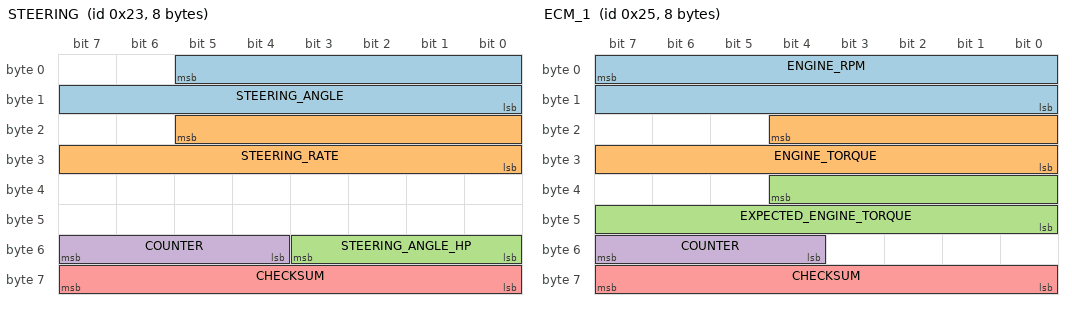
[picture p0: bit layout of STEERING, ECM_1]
BO_ 35 STEERING: 8 XXX
 SG_ STEERING_ANGLE : 5|14@0+ (0.5,-2048) [-2048|2047] "deg" XXX
 SG_ STEERING_RATE : 21|14@0+ (0.5,-2048) [-2048|2047] "deg/s" XXX
 SG_ STEERING_ANGLE_HP : 48|4@1+ (0.1,-0.4) [-0.4|0.4] "deg" XXX
 SG_ COUNTER : 55|4@0+ (1,0) [0|15] "" XXX
 SG_ CHECKSUM : 63|8@0+ (1,0) [0|255] "" XXX

BO_ 37 ECM_1: 8 XXX
 SG_ ENGINE_RPM : 7|16@0+ (1,0) [0|65535] "" XXX
 SG_ ENGINE_TORQUE : 20|13@0+ (0.25,-500) [-500|1547.5] "Nm" XXX
 SG_ EXPECTED_ENGINE_TORQUE : 36|13@0+ (0.25,-500) [-500|1547.5] "Nm" XXX
 SG_ COUNTER : 55|4@0+ (1,0) [0|15] "" XXX
 SG_ CHECKSUM : 63|8@0+ (1,0) [0|255] "" XXX

BO_ 181 ECM_TRQ: 8 XXX
 SG_ ENGINE_TORQ_MAX : 4|13@0+ (.25,-500) [-500|1547.5] "NM" XXX
 SG_ ENGINE_TORQ_MIN : 20|13@0+ (.25,-500) [-500|1547.5] "NM" XXX

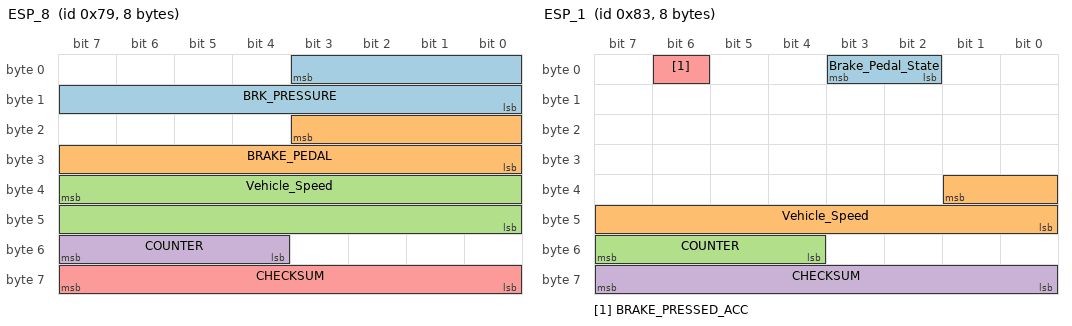
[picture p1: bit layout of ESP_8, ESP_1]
BO_ 121 ESP_8: 8 XXX
 SG_ BRK_PRESSURE : 3|12@0+ (1,0) [0|1] "" XXX
 SG_ BRAKE_PEDAL : 19|12@0+ (1,0) [0|1] "" XXX
 SG_ Vehicle_Speed : 39|16@0+ (0.0078125,0) [0|511.984375] "km/h" XXX
 SG_ COUNTER : 55|4@0+ (1,0) [0|15] "" XXX
 SG_ CHECKSUM : 63|8@0+ (1,0) [0|255] "" XXX

BO_ 131 ESP_1: 8 XXX
 SG_ Brake_Pedal_State : 2|2@1+ (1,0) [0|0] "" XXX
 SG_ Vehicle_Speed : 33|10@0+ (0.5,0) [0|511] "km/h" XXX
 SG_ COUNTER : 55|4@0+ (1,0) [0|15] "" XXX
 SG_ CHECKSUM : 63|8@0+ (1,0) [0|255] "" XXX
 SG_ BRAKE_PRESSED_ACC : 6|1@0+ (1,0) [0|3] "" XXX

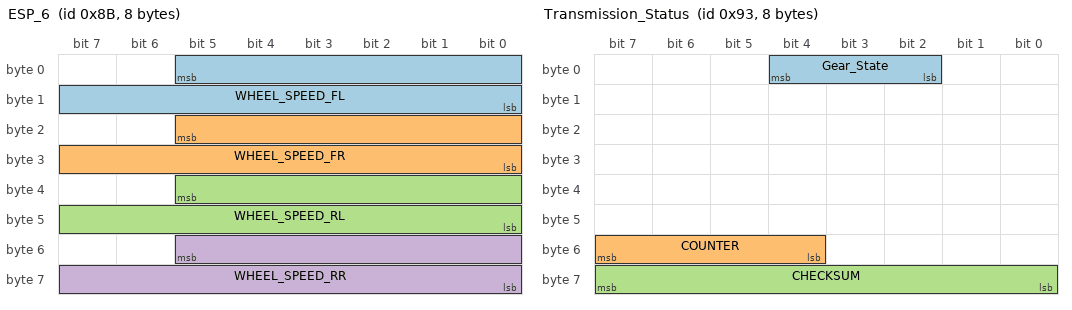
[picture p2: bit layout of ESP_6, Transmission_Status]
BO_ 139 ESP_6: 8 XXX
 SG_ WHEEL_SPEED_FL : 5|14@0+ (0.5,0) [0|8191] "rpm" XXX
 SG_ WHEEL_SPEED_FR : 21|14@0+ (0.5,0) [0|8191] "rpm" XXX
 SG_ WHEEL_SPEED_RL : 37|14@0+ (0.5,0) [0|8191] "rpm" XXX
 SG_ WHEEL_SPEED_RR : 53|14@0+ (0.5,0) [0|8191] "rpm" XXX

BO_ 147 Transmission_Status: 8 XXX
 SG_ Gear_State : 2|3@1+ (1,0) [0|15] "" XXX
 SG_ COUNTER : 55|4@0+ (1,0) [0|15] "" XXX
 SG_ CHECKSUM : 63|8@0+ (1,0) [0|255] "" XXX

BO_ 464 ORC_1: 8 XXX
 SG_ SEATBELT_DRIVER_UNLATCHED : 13|1@0+ (1,0) [0|1] "" XXX

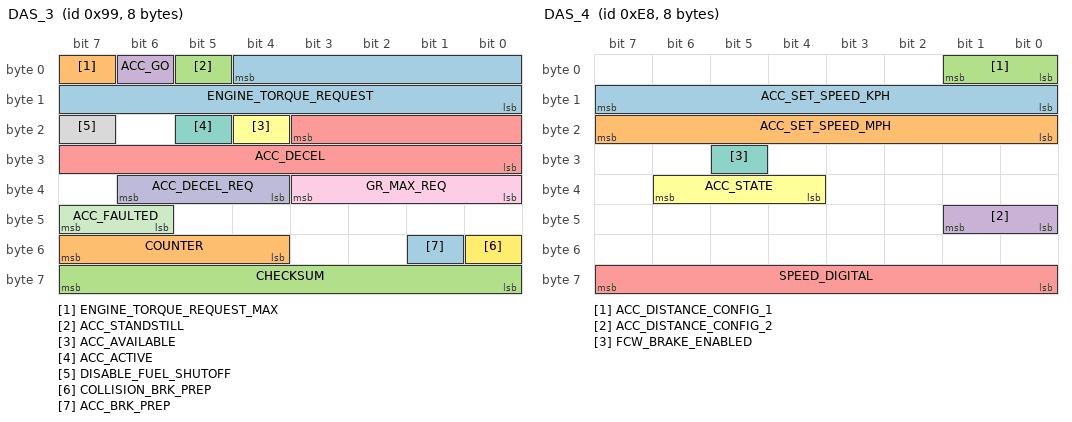
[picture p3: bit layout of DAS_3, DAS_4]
BO_ 153 DAS_3: 8 XXX
 SG_ ENGINE_TORQUE_REQUEST : 4|13@0+ (0.25,-500) [-500|1547.5] "Nm" XXX
 SG_ ENGINE_TORQUE_REQUEST_MAX : 7|1@0+ (1,0) [0|1] "" XXX
 SG_ ACC_STANDSTILL : 5|1@0+ (1,0) [0|1] ""  XXX
 SG_ ACC_GO : 6|1@1+ (1,0) [0|0] "" XXX
 SG_ ACC_DECEL : 19|12@0+ (0.004885,-16) [-16|4] "m/s2" XXX
 SG_ ACC_AVAILABLE : 20|1@0+ (1,0) [0|1] "" XXX
 SG_ ACC_ACTIVE : 21|1@0+ (1,0) [0|1] "" XXX
 SG_ DISABLE_FUEL_SHUTOFF : 23|1@1+ (1,0) [0|0] "" XXX
 SG_ GR_MAX_REQ : 32|4@1+ (1,0) [0|0] "" XXX
 SG_ ACC_DECEL_REQ : 36|3@1+ (1,0) [0|0] "" XXX
 SG_ ACC_FAULTED : 46|2@1+ (1,0) [0|0] "" XXX
 SG_ COLLISION_BRK_PREP : 48|1@1+ (1,0) [0|0] "" XXX
 SG_ ACC_BRK_PREP : 49|1@1+ (1,0) [0|0] "" XXX
 SG_ COUNTER : 55|4@0+ (1,0) [0|15] "" XXX
 SG_ CHECKSUM : 63|8@0+ (1,0) [0|255] "" XXX

BO_ 232 DAS_4: 8 XXX
 SG_ ACC_SET_SPEED_KPH : 15|8@0+ (1,0) [0|3] "km/h" XXX
 SG_ ACC_SET_SPEED_MPH : 23|8@0+ (1,0) [0|3] "mph" XXX
 SG_ ACC_DISTANCE_CONFIG_1 : 1|2@0+ (1,0) [0|3] "" XXX
 SG_ ACC_DISTANCE_CONFIG_2 : 41|2@0+ (1,0) [0|3] "" XXX
 SG_ SPEED_DIGITAL : 63|8@0+ (1,0) [0|255] "mph" XXX
 SG_ ACC_STATE : 38|3@0+ (1,0) [0|7] "" XXX
 SG_ FCW_BRAKE_ENABLED : 29|1@0+ (1,0) [0|1] "" XXX

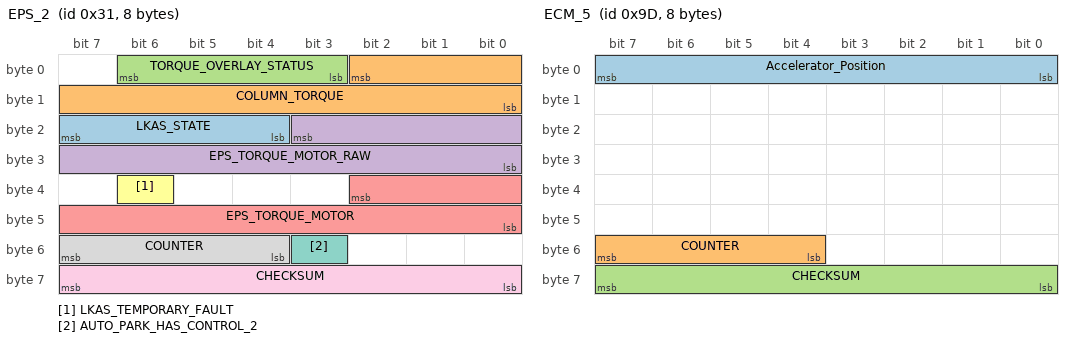
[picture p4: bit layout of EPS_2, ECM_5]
BO_ 49 EPS_2: 8 XXX
 SG_ LKAS_STATE : 23|4@0+ (1,0) [0|15] "" XXX
 SG_ COLUMN_TORQUE : 2|11@0+ (1,-1024) [-1024|1023] "" XXX
 SG_ TORQUE_OVERLAY_STATUS : 6|4@0+ (1,0) [0|15] "" XXX
 SG_ EPS_TORQUE_MOTOR_RAW : 19|12@0+ (1,-2048) [-2048|2047] "" XXX
 SG_ EPS_TORQUE_MOTOR : 34|11@0+ (1,-1024) [-1024|1023] "" XXX
 SG_ LKAS_TEMPORARY_FAULT : 38|1@0+ (1,0) [0|1] "" XXX
 SG_ AUTO_PARK_HAS_CONTROL_2 : 51|1@0+ (1,0) [0|1] "" XXX
 SG_ COUNTER : 55|4@0+ (1,0) [0|15] "" XXX
 SG_ CHECKSUM : 63|8@0+ (1,0) [0|255] "" XXX

BO_ 157 ECM_5: 8 XXX
 SG_ Accelerator_Position : 0|8@1+ (0.4,0) [0|100] "%" XXX
 SG_ COUNTER : 55|4@0+ (1,0) [0|15] "" XXX
 SG_ CHECKSUM : 63|8@0+ (1,0) [0|255] "" XXX

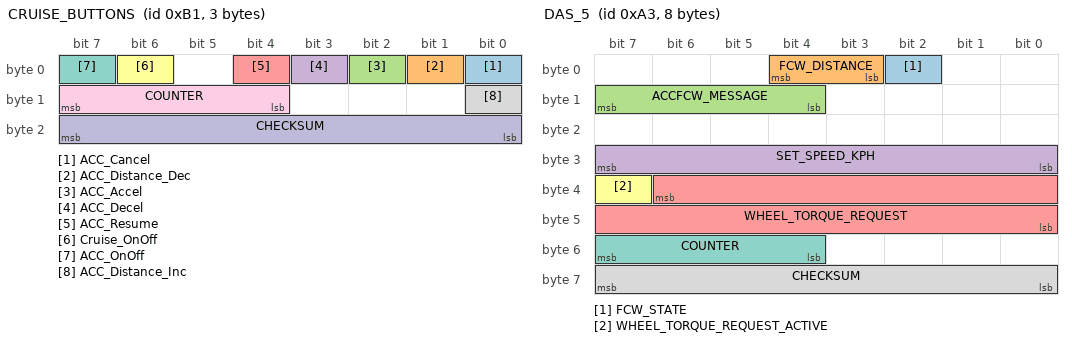
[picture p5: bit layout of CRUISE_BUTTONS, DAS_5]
BO_ 177 CRUISE_BUTTONS: 3 XXX
 SG_ ACC_Cancel : 0|1@1+ (1,0) [0|0] "" XXX
 SG_ ACC_Distance_Dec : 1|1@1+ (1,0) [0|0] "" XXX
 SG_ ACC_Accel : 2|1@1+ (1,0) [0|0] "" XXX
 SG_ ACC_Decel : 3|1@1+ (1,0) [0|0] "" XXX
 SG_ ACC_Resume : 4|1@0+ (1,0) [0|1] "" XXX
 SG_ Cruise_OnOff : 6|1@1+ (1,0) [0|0] "" XXX
 SG_ ACC_OnOff : 7|1@1+ (1,0) [0|0] "" XXX
 SG_ ACC_Distance_Inc : 8|1@1+ (1,0) [0|0] "" XXX
 SG_ COUNTER : 15|4@0+ (1,0) [0|15] "" XXX
 SG_ CHECKSUM : 23|8@0+ (1,0) [0|255] "" XXX

BO_ 163 DAS_5: 8 XXX
 SG_ FCW_STATE : 2|1@1+ (1,0) [0|0] ""  XXX
 SG_ FCW_DISTANCE : 3|2@1+ (1,0) [0|0] ""  XXX
 SG_ ACCFCW_MESSAGE : 12|4@1+ (1,0) [0|0] ""  XXX
 SG_ SET_SPEED_KPH : 24|8@1+ (1,0) [0|250] "km/h"  XXX
 SG_ WHEEL_TORQUE_REQUEST : 38|15@0+ (1,-7767) [-7767|24999] "Nm"  XXX
 SG_ WHEEL_TORQUE_REQUEST_ACTIVE : 39|1@1+ (1,0) [0|0] ""  XXX
 SG_ COUNTER : 55|4@0+ (1,0) [0|15] "" XXX
 SG_ CHECKSUM : 63|8@0+ (1,0) [0|255] "" XXX

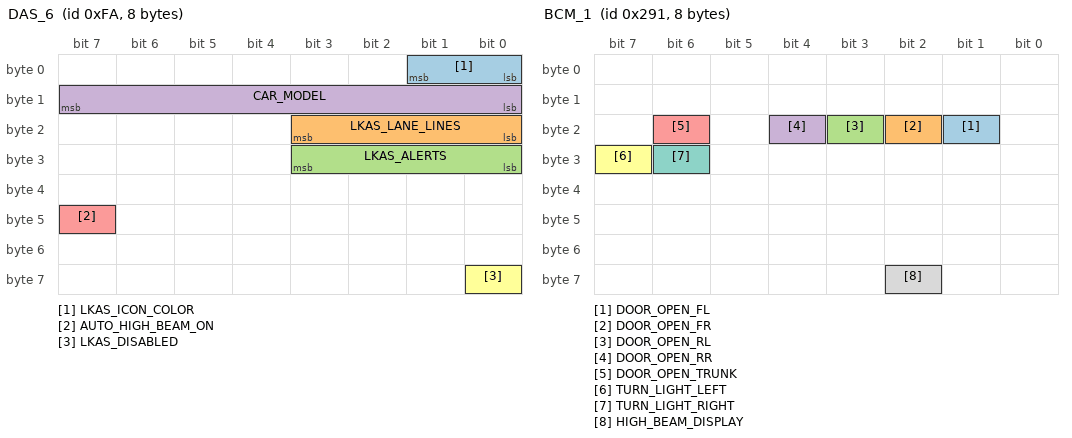
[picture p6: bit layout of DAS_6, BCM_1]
BO_ 250 DAS_6: 8 XXX
 SG_ LKAS_ICON_COLOR : 1|2@0+ (1,0) [0|3] "" XXX
 SG_ LKAS_LANE_LINES : 19|4@0+ (1,0) [0|1] "" XXX
 SG_ LKAS_ALERTS : 27|4@0+ (1,0) [0|1] "" XXX
 SG_ CAR_MODEL : 15|8@0+ (1,0) [0|255] "" XXX
 SG_ AUTO_HIGH_BEAM_ON : 47|1@1+ (1,0) [0|0] "" XXX
 SG_ LKAS_DISABLED : 56|1@1+ (1,0) [0|0] "" XXX

BO_ 720 BSM_1: 6 XXX
 SG_ RIGHT_STATUS : 5|1@0+ (1,0) [0|1] "" XXX
 SG_ LEFT_STATUS : 2|1@0+ (1,0) [0|1] "" XXX

BO_ 792 STEERING_LEVERS: 8 XXX
 SG_ TURN_SIGNALS : 0|2@1+ (1,0) [0|3] "" XXX
 SG_ HIGH_BEAM_PRESSED : 2|1@0+ (1,0) [0|3] "" XXX

BO_ 657 BCM_1: 8 XXX
 SG_ DOOR_OPEN_FL : 17|1@0+ (1,0) [0|1] "" XXX
 SG_ DOOR_OPEN_FR : 18|1@0+ (1,0) [0|1] "" XXX
 SG_ DOOR_OPEN_RL : 19|1@0+ (1,0) [0|1] "" XXX
 SG_ DOOR_OPEN_RR : 20|1@0+ (1,0) [0|1] "" XXX
 SG_ DOOR_OPEN_TRUNK : 22|1@0+ (1,0) [0|1] "" XXX
 SG_ TURN_LIGHT_LEFT : 31|1@0+ (1,0) [0|1] "" XXX
 SG_ TURN_LIGHT_RIGHT : 30|1@0+ (1,0) [0|1] "" XXX
 SG_ HIGH_BEAM_DISPLAY : 58|1@0+ (1,0) [0|1] "" XXX

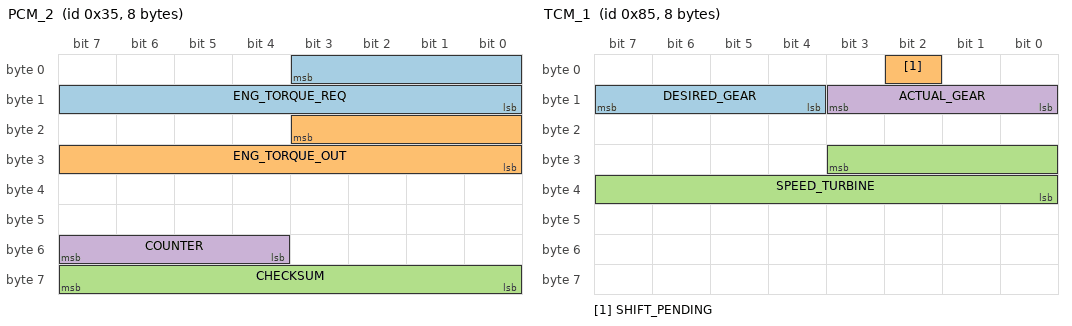
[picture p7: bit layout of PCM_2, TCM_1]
BO_ 53 PCM_2: 8 XXX
 SG_ ENG_TORQUE_REQ : 3|12@0+ (1,0) [0|7] "" XXX
 SG_ ENG_TORQUE_OUT : 19|12@0+ (1,0) [0|1] "" XXX
 SG_ CHECKSUM : 63|8@0+ (1,0) [0|255] "" XXX
 SG_ COUNTER : 55|4@0+ (1,0) [0|15] "" XXX

BO_ 133 TCM_1: 8 XXX
 SG_ DESIRED_GEAR : 15|4@0+ (1,0) [0|1] "" XXX
 SG_ SHIFT_PENDING : 2|1@0+ (1,0) [0|1] "" XXX
 SG_ SPEED_TURBINE : 27|12@0+ (0.04,0) [0|1] "km/h" XXX
 SG_ ACTUAL_GEAR : 11|4@0+ (1,0) [0|15] "" XXX

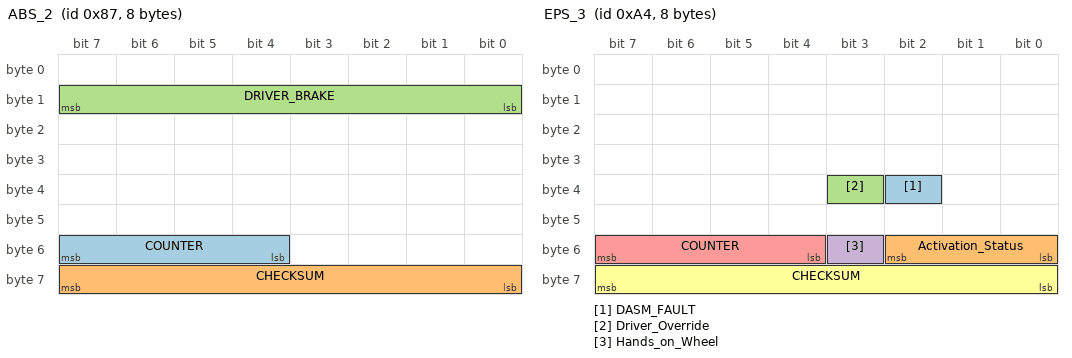
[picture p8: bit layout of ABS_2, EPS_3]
BO_ 135 ABS_2: 8 XXX
 SG_ COUNTER : 55|4@0+ (1,0) [0|1] "" XXX
 SG_ CHECKSUM : 63|8@0+ (1,0) [0|1] "" XXX
 SG_ DRIVER_BRAKE : 15|8@0+ (1,0) [0|1] "" XXX

BO_ 137 ESP_4: 8 XXX
 SG_ Yaw_Rate : 7|16@0+ (0.01,-327.68) [-327.68|327.66] "deg/s" XXX
 SG_ Acceleration : 32|8@1+ (0.08,-10.24) [-10.24|10.08] "m/s2" XXX

BO_ 164 EPS_3: 8 XXX
 SG_ DASM_FAULT : 34|1@0+ (1,0) [0|1] "" XXX
 SG_ Activation_Status : 48|3@1+ (1,0) [0|1] "" XXX
 SG_ Driver_Override : 35|1@0+ (1,0) [0|1] "" XXX
 SG_ Hands_on_Wheel : 51|1@0+ (1,0) [0|1] "" XXX
 SG_ COUNTER : 55|4@0+ (1,0) [0|15] "" XXX
 SG_ CHECKSUM : 63|8@0+ (1,0) [0|255] "" XXX

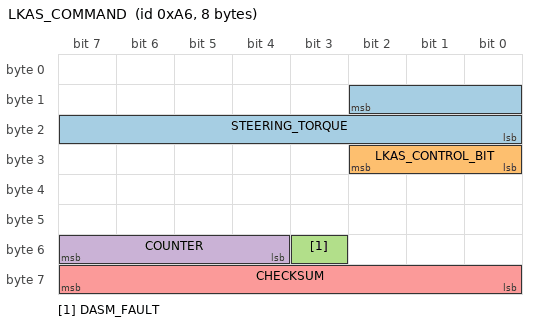
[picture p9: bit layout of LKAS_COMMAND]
BO_ 166 LKAS_COMMAND: 8 XXX
 SG_ STEERING_TORQUE : 10|11@0+ (1,-1024) [0|1] "" XXX
 SG_ LKAS_CONTROL_BIT : 24|3@1+ (1,0) [0|1] "" XXX
 SG_ DASM_FAULT : 51|1@0+ (1,0) [0|1] "" XXX
 SG_ COUNTER : 55|4@0+ (1,0) [0|15] "" XXX
 SG_ CHECKSUM : 63|8@0+ (1,0) [0|255] "" XXX

BO_ 221 Center_Stack_1: 8 XXX
 SG_ LKAS_Button : 53|1@1+ (1,0) [0|0] "" XXX
 SG_ Traction_Button : 54|1@0+ (1,0) [0|1] "" XXX

BO_ 650 Center_Stack_2: 8 XXX
 SG_ LKAS_Button : 57|1@1+ (1,0) [0|0] "" XXX

BU_: XXX

CM_ "AUTOGENERATED FILE, DO NOT EDIT";

CM_ "Imported file _comma.dbc starts here";
CM_ "BO_ STEERING_IPAS_COMMA: Copy of msg 614 so we can do angle control while the Park Assist ECU is connected (Panda spoofs 614 with 359 on connector J70). Note that addresses 0x266 and 0x167 are checksum-invariant";

CM_ "BO_ SECONDARY_STEER_ANGLE: ZSS is a high-precision steering angle sensor that can replace the lower resolution sensor in most TSS1 Toyotas. Learn more: https://github.com/commaai/openpilot/wiki/Toyota-Lexus#zorro-steering-sensor-zss";

CM_ "BO_ SDSU: The sDSU is a modified DSU for use in TSS1 Toyotas. Learn more: https://github.com/wocsor/panda/tree/smart_dsu";
CM_ SG_ 767 FD_BUTTON "The follow distance button signal as forwarded by the sdsu";

CM_ "Imported file _toyota_2017.dbc starts here";
CM_ SG_ 36 YAW_RATE "verify";
CM_ SG_ 36 ACCEL_X "x-axis accel";
CM_ SG_ 37 STEER_FRACTION "1/15th of the signal STEER_ANGLE, which is 1.5 deg; note that 0x8 is never set";
CM_ SG_ 37 STEER_RATE "factor is tbd";
CM_ SG_ 466 NEUTRAL_FORCE "force in newtons the engine/electric motors are applying without any acceleration commands or user input";
CM_ SG_ 466 ACC_BRAKING "whether brakes are being actuated from ACC command";
CM_ SG_ 466 ACCEL_NET "net acceleration produced by the system, given ACCEL_CMD, road grade and other factors";
CM_ SG_ 466 CRUISE_STATE "Active state is 8, if standstill is requested will switch to state 11(3 sec timer), after timer is elapsed will switch into state 7(standstill). If plus button was pressed - status 9, minus button pressed - status 10";
CM_ SG_ 467 ACC_FAULTED "1 when ACC is faulted and the PCM disallows engagement";
CM_ SG_ 467 SET_SPEED "43 km/h are shown as 28 mph, so conversion isn't perfect";
CM_ SG_ 467 LOW_SPEED_LOCKOUT "in low speed lockout, system would always disengage below 28mph";
CM_ SG_ 560 BRAKE_PRESSED "another brake pressed?";
CM_ SG_ 581 GAS_PEDAL "it seems slightly filtered";
CM_ SG_ 608 STEER_TORQUE_DRIVER "driver torque";
CM_ SG_ 608 STEER_OVERRIDE "set when driver torque exceeds a certain value";
CM_ SG_ 614 ANGLE "set to measured angle when ipas control isn't active";
CM_ SG_ 643 _COUNTER "only used on cars that use this msg for cruise control";
CM_ SG_ 643 BRAKE_STATUS "only used on cars that use this msg for cruise control";
CM_ SG_ 643 PRECOLLISION_ACTIVE "set 0.5s before any braking";
CM_ SG_ 835 ACC_TYPE "if 2, car is likely to have a permanent low speed lockout. 1 is ok";
CM_ SG_ 835 RADAR_DIRTY "Display Clean Radar Sensor message on HUD";
CM_ SG_ 835 ACC_MALFUNCTION "display ACC fault on dash if set to 1";
CM_ SG_ 835 ACC_CUT_IN "Display blinking yellow lead if set to 1";
CM_ SG_ 835 DISTANCE "Cycle through ACC following distance from long, mid, short when set to 1";
CM_ SG_ 835 ITS_CONNECT_LEAD "Displayed when lead car is capable of ITS Connect";
CM_ SG_ 835 ALLOW_LONG_PRESS "Enable Toyota's factory set speed increment behaviour, available on both metrics cars and imperial unit cars";
CM_ SG_ 835 PERMIT_BRAKING "Original ACC has this going high when a car in front is detected. In openpilot and before the PERMIT_BRAKING name, this was 'SET_ME_1' and is hardcoded to be high. Unsure if only informational or has an effect though existing usage in openpilot is to always set it to 1. Originally 'PMTBRKG' in the leaked toyota_2017_ref_pt.dbc file and name expansion speculated to be PerMiT BRaKinG.";
CM_ SG_ 835 ACCEL_CMD_ALT "Copy of main ACCEL_CMD, but across 8 bits instead of 16 bits like ACCEL_CMD. Unsure if only informational or has an effect. Likely informational as existing openpilot sets this to 0 and no loss of functionality observed. Originally 'AT_RAW' in leaked toyota_2017_ref_pt.dbc file.";
CM_ SG_ 865 GAS_PEDAL_ALT "copy of main GAS_PEDAL. Both use 8 bits. Might indicate that this message is for pedals.";
CM_ SG_ 865 CLUTCH_RELEASED "boolean of clutch for 6MT.";
CM_ SG_ 865 ACC_FAULTED "1 when ACC is faulted and the PCM disallows engagement. Also describes a lockout when the ACC_CONTROL->ACC_MALFUNCTION bit is set.";
CM_ SG_ 921 UI_SET_SPEED "set speed shown in the vehicle's UI with the vehicle's unit";
CM_ SG_ 921 TEMP_ACC_FAULTED "1 when the UI is displaying or playing fault-related alerts or sounds. Also 1 when pressing main on.";
CM_ SG_ 951 BRAKE_LIGHTS_ACC "brake lights when ACC commands decel";
CM_ SG_ 956 GEAR "on 6MT, only R shows.";
CM_ SG_ 1009 UI_SET_SPEED "units seem to be whatever the car is set to";
CM_ SG_ 1041 PCS_INDICATOR "Pre-Collision System Indicator";
CM_ SG_ 1041 PCS_SENSITIVITY "Pre-Collision System Sensitivity";
CM_ SG_ 1041 PCS_DUST "alert: Front Camera Low Visibility Unavailable See Owner's Manual";
CM_ SG_ 1041 PCS_DUST2 "alert: Pre-Collision System Radar Sensor Blocked Unavailable Clean Radar Sensor";
CM_ SG_ 1041 PCS_TEMP "alert: Front Camera Out of Temperature Range Unavailable Wait until Normal Temperature";
CM_ SG_ 1041 PCS_TEMP2 "alert: Pre-Collision System Out of Temperature Range Unavailable See Owner's Manual";
CM_ SG_ 1041 FRD_ADJ "alert: ERROR ADJUSTING FRONT RADAR BEAM";
CM_ SG_ 1042 LDA_SA_TOGGLE "LDA Steering Assist Toggle";
CM_ SG_ 1042 LDW_EXIST "Unclear what this is, it's usually set to 0";
CM_ SG_ 1042 LDA_SENSITIVITY "LDA Sensitivity";
CM_ SG_ 1042 LDA_ON_MESSAGE "Display LDA Turned ON message";
CM_ SG_ 1042 REPEATED_BEEPS "LDA audible warning";
CM_ SG_ 1042 LDA_UNAVAILABLE_QUIET "LDA toggles and sensitivity settings are greyed out if set to 1";
CM_ SG_ 1042 LDA_MESSAGES "Various LDA Messages";
CM_ SG_ 1042 LDA_FRONT_CAMERA_BLOCKED "originally LDAFCVB, LDA related settings are greyed out if set to 1";
CM_ SG_ 1042 TAKE_CONTROL "Please Control Steering Wheel warning";
CM_ SG_ 1042 LANE_SWAY_TOGGLE "Lane Sway Warning System SWS Switch";
CM_ SG_ 1042 LANE_SWAY_WARNING "Lane Sway Warning System Triggered";
CM_ SG_ 1042 LANE_SWAY_FLD "Unknown signal for Lane Sway Warning System, set to 7 on stock system when SWS is enabled, 0 when SWS is disabled";
CM_ SG_ 1042 LANE_SWAY_BUZZER "Similar to TWO_BEEPS";
CM_ SG_ 1042 SET_ME_X01 "empty bit on leaked dbc, always set to 1 during normal operations";
CM_ SG_ 1042 SET_ME_X02 "empty bit on leaked dbc, always set to 2 during normal operations";
CM_ SG_ 1083 STATE "when the dashboard button is pressed, the value changes from zero to non-zero";
CM_ SG_ 1161 SPDVAL1 "Numbers 0-199 is displayed, 200-254 displays circle without number and 255 is for no limit.";
CM_ SG_ 1161 SYNCID1 "counter from 1 to f at 1 Hz";
CM_ SG_ 1161 SPDVAL2 "conditional speed value 70";
CM_ SG_ 1162 SGNNUMP "1 if SPDVAL1 is set, otherwise 0";
CM_ SG_ 1162 SYNCID2 "counter from 1 to f at 1 Hz";
CM_ SG_ 1163 TSREQPD "always 1";
CM_ SG_ 1163 TSRMSW "always 1";
CM_ SG_ 1163 OTSGNNTM "always 3";
CM_ SG_ 1163 NTLVLSPD "always 3";
CM_ SG_ 1163 OVSPNTM "always 3";
CM_ SG_ 1163 OVSPVALL "-5 at start then 2 after 2 seconds";
CM_ SG_ 1163 OVSPVALM "-5 at start then 5 after 2 seconds";
CM_ SG_ 1163 OVSPVALH "-5 at start then 10 after 2 seconds";
CM_ SG_ 1163 TSRSPU "always 1";
CM_ SG_ 1552 UI_SPEED "Does not appear to match dash";
CM_ SG_ 1552 METER_SLIDER_BRIGHTNESS_PCT "Combination display brightness setting, scales from 12 per cent to 100 per cent, reflects combination meter settings only, not linked with headlight state";
CM_ SG_ 1552 METER_SLIDER_LOW_BRIGHTNESS "Combination display low brightness mode, also controls footwell lighting";
CM_ SG_ 1552 METER_SLIDER_DIMMED "Combination display slider not at max, reflects combination meter settings only, not linked with headlight state";
CM_ SG_ 1553 ODOMETER "Unit is dependent upon units signal";
CM_ SG_ 1592 LOCK_STATUS_CHANGED "1 on rising edge of lock/unlocking";
CM_ SG_ 1592 LOCK_STATUS "The next 3 bits always seem to follow this signal.";
CM_ SG_ 1592 LOCKED_VIA_KEYFOB "1 for as long as car is locked with key fob or door handle touch";

CM_ "toyota_nodsu_pt.dbc starts here";

CM_ SG_ 401 PERCENTAGE "driver override percentage (0-100), very close to steeringPressed in OP";
CM_ SG_ 401 TORQUE_WIND_DOWN "used to wind down torque on user override";
CM_ SG_ 401 ANGLE "angle of car relative to lane center on LTA camera";
CM_ SG_ 401 STEER_ANGLE_CMD "desired angle, OEM steers up to 95 degrees, no angle limit but torque will bottom out";
CM_ SG_ 401 CLEAR_HOLD_STEERING_ALERT "set to 1 when user clears LKAS_HUD->LDA_ALERT ('Hold Steering') by applying torque to steering wheel";
CM_ SG_ 401 STEER_REQUEST "enable bit for steering, 1 to steer, 0 to not";
CM_ SG_ 401 STEER_REQUEST_2 "enable bit for steering, 1 to steer, 0 to not";
CM_ SG_ 401 LKA_ACTIVE "1 when using LTA for LKA";
CM_ SG_ 401 SETME_X1 "usually 1, seen at 0 on some South American Corollas indicating lack of stock Lane Tracing Assist";
CM_ SG_ 401 SETME_X3 "almost completely correlates with Toyota Safety Sense version, but may instead describe max torque when using LTA. if TSS 2.5 or 2022 RAV4, this is always 1. if TSS 2.0 this is always 3 (or 0 on Alphard, Highlander, NX)";
CM_ SG_ 550 BRAKE_PRESSURE "seems prop to pedal force";
CM_ SG_ 550 BRAKE_POSITION "seems proportional to pedal displacement, unclear the max value of 0x1c8";
CM_ SG_ 610 TYPE "seems 1 on Corolla, 0 on all others";
CM_ SG_ 881 GAS_PEDAL "not set on all cars, only seen on TSS 2.5 Camry Hybrid so far";
CM_ SG_ 881 STEER_ANGLE "matches STEER_TORQUE_SENSOR->STEER_ANGLE";
CM_ SG_ 881 TURN_SIGNALS "flipped on some cars";
CM_ SG_ 881 LDA_SA_TOGGLE "not applicable for all cars";
CM_ SG_ 881 LTA_STEER_REQUEST "only applicable for TSS 2.5: matches STEERING_LTA->STEER_REQUEST";
CM_ SG_ 881 UNKNOWN "related to steering wheel angle";
CM_ SG_ 881 STEERING_PRESSED "only applicable for TSS 2.5: low sensitivity steering wheel pressed by driver signal";
CM_ SG_ 1014 L_ADJACENT "vehicle adjacent left side of car. enabled above 10mph, regardless of ADJACENT_ENABLED or APPROACHING_ENABLED";
CM_ SG_ 1014 L_APPROACHING "vehicle approaching from left side of car. enabled above 10mph, regardless of ADJACENT_ENABLED or APPROACHING_ENABLED";
CM_ SG_ 1014 R_ADJACENT "vehicle adjacent right side of car. enabled above 10mph, regardless of ADJACENT_ENABLED or APPROACHING_ENABLED";
CM_ SG_ 1014 R_APPROACHING "vehicle approaching from right side of car. enabled above 10mph, regardless of ADJACENT_ENABLED or APPROACHING_ENABLED";
CM_ SG_ 1014 ADJACENT_ENABLED "when BSM is enabled in settings, this is on along with APPROACHING_ENABLED. this controls bsm alert visibility";
CM_ SG_ 1014 APPROACHING_ENABLED "when BSM is enabled in settings, this is on along with ADJACENT_ENABLED. this controls bsm alert visibility";
